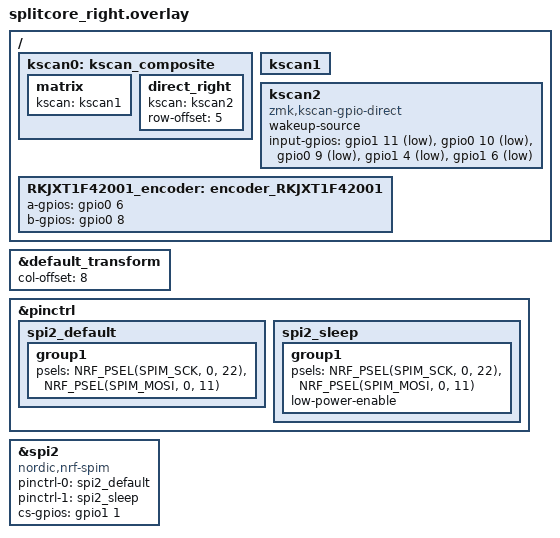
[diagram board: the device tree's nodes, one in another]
#include "splitcore.dtsi"

&default_transform { // Offset of 8 because the left side has 8 columns
    col-offset = <8>;
};

/ {

    kscan0: kscan_composite {
        // matrix driver
        matrix {
            kscan = <&kscan1>;
        };
        // direct GPIO driver for RKJXT1F42001 buttons
        direct_right {
            kscan = <&kscan2>;
            row-offset = <5>;
        };
    };

    kscan1: kscan1 {
        status = "okay";
    };

    // RKJXT1F42001 buttons
    kscan2: kscan2 {
        compatible = "zmk,kscan-gpio-direct";
        wakeup-source;
        status = "okay";
        input-gpios
            = <&gpio1 11    (GPIO_ACTIVE_LOW | GPIO_PULL_UP)>
            , <&gpio0 10    (GPIO_ACTIVE_LOW | GPIO_PULL_UP)>
            , <&gpio0 9     (GPIO_ACTIVE_LOW | GPIO_PULL_UP)>
            , <&gpio1 4     (GPIO_ACTIVE_LOW | GPIO_PULL_UP)>
            , <&gpio1 6     (GPIO_ACTIVE_LOW | GPIO_PULL_UP)>
            ;
    };

    RKJXT1F42001_encoder: encoder_RKJXT1F42001 {
        status = "okay";
        a-gpios = <&gpio0 6 (GPIO_ACTIVE_HIGH | GPIO_PULL_UP)>;
        b-gpios = <&gpio0 8 (GPIO_ACTIVE_HIGH | GPIO_PULL_UP)>;
    };
};

&pinctrl {
    // spi for the nice view display
    spi2_default: spi2_default {
        group1 {
            psels = <NRF_PSEL(SPIM_SCK, 0, 22)>,
                    <NRF_PSEL(SPIM_MOSI, 0, 11)>;
        };
    };
    spi2_sleep: spi2_sleep {
        group1 {
            psels = <NRF_PSEL(SPIM_SCK, 0, 22)>,
                    <NRF_PSEL(SPIM_MOSI, 0, 11)>;
            low-power-enable;
        };
    };
};

nice_view_spi: &spi2 {
    compatible = "nordic,nrf-spim";
    pinctrl-0 = <&spi2_default>;
    pinctrl-1 = <&spi2_sleep>;
    pinctrl-names = "default", "sleep";
    cs-gpios = <&gpio1 1 GPIO_ACTIVE_HIGH>;
};

#include "splitcore_trackpoint.dtsi"
